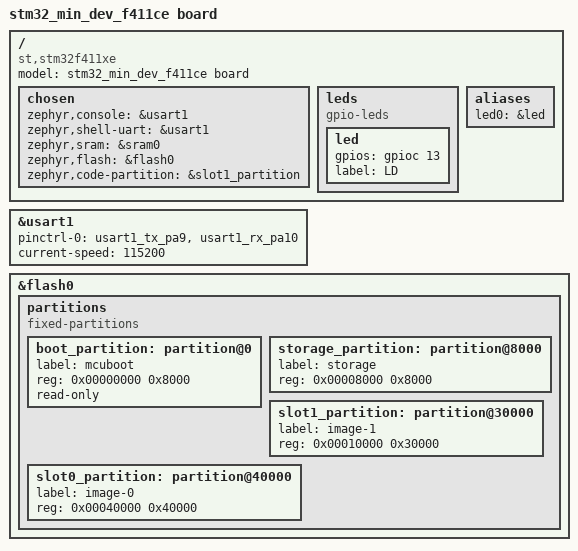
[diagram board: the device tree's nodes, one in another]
/*
 * Copyright (c) 2017 Linaro Limited
 * Copyright (c) 2019 Centaur Analytics, Inc
 *
 * SPDX-License-Identifier: Apache-2.0
 */

/dts-v1/;
#include <st/f4/stm32f411Xe.dtsi>
#include <st/f4/stm32f411c(c-e)ux-pinctrl.dtsi>



/ {
	model = "stm32_min_dev_f411ce board";
	compatible = "st,stm32f411xe";

	chosen {
		zephyr,console = &usart1;
		zephyr,shell-uart = &usart1;
		zephyr,sram = &sram0;
		zephyr,flash = &flash0;
		zephyr,code-partition = &slot1_partition;
	};

	leds {
		compatible = "gpio-leds";
		led: led {
			gpios = <&gpioc 13 GPIO_ACTIVE_HIGH>;
			label = "LD";
		};
	};

	aliases {
		led0 = &led;
	};

};

&usart1 {
	pinctrl-0 = <&usart1_tx_pa9 &usart1_rx_pa10>;
	current-speed = <115200>;
	status = "okay";
};

&flash0 {
	/*
	 * For more information, see:
	 * https://docs.zephyrproject.org/latest/reference/devicetree/index.html#fixed-flash-partitions
	 */
	partitions {
		compatible = "fixed-partitions";
		#address-cells = <1>;
		#size-cells = <1>;

		/* KB for bootloader */
		boot_partition: partition@0 {
			label = "mcuboot";
			reg = <0x00000000 0x8000>;
			read-only;
		};

		/* storage: 32KB for settings */
		storage_partition: partition@8000 {
			label = "storage";
			reg = <0x00008000 0x8000>;
		};

		/* backup slot: 192KB */
		slot1_partition: partition@30000 {
			label = "image-1";
			reg = <0x00010000 0x30000>;
		};

		/* application image slot: 256KB */
		slot0_partition: partition@40000 {
			label = "image-0";
			reg = <0x00040000 0x40000>;
		};

	};
};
